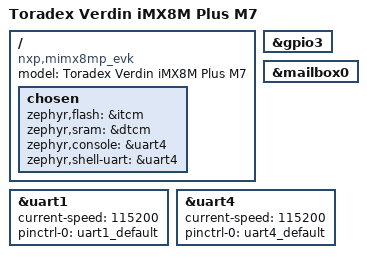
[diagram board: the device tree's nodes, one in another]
/*
 * Copyright (c) 2023 Toradex
 *
 * SPDX-License-Identifier: Apache-2.0
 */

/dts-v1/;

#include <nxp/nxp_imx8ml_m7.dtsi>
#include "verdin_imx8mp-pinctrl.dtsi"
#include <zephyr/dt-bindings/input/input-event-codes.h>

/ {
	model = "Toradex Verdin iMX8M Plus M7";
	compatible = "nxp,mimx8mp_evk";

	chosen {
		/* TCM */
		zephyr,flash = &itcm;
		zephyr,sram = &dtcm;

		zephyr,console = &uart4;
		zephyr,shell-uart = &uart4;
	};
};

&gpio3 {
	status = "okay";
};

&mailbox0 {
	status = "okay";
};

&uart1 {
	current-speed = <115200>;
	pinctrl-0 = <&uart1_default>;
	pinctrl-names = "default";
};

&uart4 {
	status = "okay";
	current-speed = <115200>;
	pinctrl-0 = <&uart4_default>;
	pinctrl-names = "default";
};
